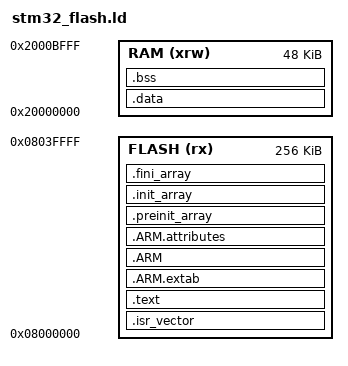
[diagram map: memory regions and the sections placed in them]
/*  Copyright (C) 2017 Bogdan Bogush <bogdan.s.bogush@gmail.com>
 *  This program is free software; you can redistribute it and/or modify
 *  it under the terms of the GNU General Public License version 3.
 */

/* Device: STM32F103
 * Flash: 256KByte
 * RAM: 48KByte
 */

ENTRY(Reset_Handler)

/* End of stack = start of RAM 0x20000000 + 48K */
_estack = 0x2000c000;

MEMORY
{
    FLASH(rx) : ORIGIN = 0x08000000, LENGTH = 256K
    RAM(xrw) : ORIGIN = 0x20000000, LENGTH = 48K
}

SECTIONS
{
    /* Startup code */
    .isr_vector :
    {
        . = ALIGN(4);
        KEEP(*(.isr_vector))
        . = ALIGN(4);
    } > FLASH

    /* Code and constant data */
    .text :
    {
        . = ALIGN(4);
        *(.text)
        *(.text*)
        *(.rodata)
        *(.rodata*)

        KEEP (*(.init))
        KEEP (*(.fini))

        . = ALIGN(4);
        _etext = .;
    } > FLASH

    /* Exception unwinding sections */
    .ARM.extab :
    {
        *(.ARM.extab* .gnu.linkonce.armextab.*)
    } > FLASH

    .ARM :
    {
        __exidx_start = .;
        *(.ARM.exidx*)
        __exidx_end = .;
    } > FLASH

    /* ARM specific attributes */
    .ARM.attributes :
    {
        *(.ARM.attributes)
    } > FLASH

    /* Initialization sections */
    .preinit_array :
    {
        PROVIDE_HIDDEN(__preinit_array_start = .);
        KEEP(*(.preinit_array*))
        PROVIDE_HIDDEN(__preinit_array_end = .);
    } > FLASH
  
    .init_array :
    {
        PROVIDE_HIDDEN(__init_array_start = .);
        KEEP(*(SORT(.init_array.*)))
        KEEP(*(.init_array*))
        PROVIDE_HIDDEN(__init_array_end = .);
    } > FLASH

    /* Termination sections */
    .fini_array :
    {
        PROVIDE_HIDDEN(__fini_array_start = .);
        KEEP(*(.fini_array*))
        KEEP(*(SORT(.fini_array.*)))
        PROVIDE_HIDDEN(__fini_array_end = .);
    } > FLASH

    /* Used by startup code to initialize data */
    _sidata = .;

    /* Initialized data sections */
    .data : AT(_sidata)
    {
        . = ALIGN(4);
        _sdata = .;
        *(.data)
	*(.data*)

        . = ALIGN(4);
        _edata = .;
    } > RAM

    /* Uninitialized data section */
    . = ALIGN(4);
    .bss :
    {
        _sbss = .;
        __bss_start__ = _sbss;
        *(.bss)
        *(.bss*)
        *(COMMON)

        . = ALIGN(4);
        _ebss = .;
        __bss_end__ = _ebss;
    } > RAM

    PROVIDE(end = _ebss);
    PROVIDE(_end = _ebss);

    /* Discard unused sections */
    /DISCARD/ :
    {
        libc.a (*)
        libm.a (*)
        libgcc.a (*)
    }
}
